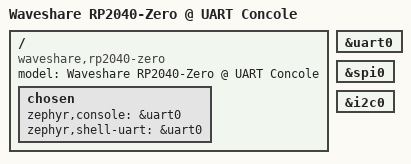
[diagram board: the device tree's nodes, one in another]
/*
 * Copyright (c) 2023-2025 TiaC Systems
 * SPDX-License-Identifier: Apache-2.0
 */

/dts-v1/;

/ {
	model = "Waveshare RP2040-Zero @ UART Concole";
	compatible = "waveshare,rp2040-zero", "waveshare,rp2040-zero-uartcons";

	chosen {
		zephyr,console = &uart0;
		zephyr,shell-uart = &uart0;
	};
};

#include "waveshare_rp2040-mini.dtsi"
#include "waveshare_rp2040-2mb.dtsi"

#include "rp2040mini_led_ws2812.dtsi"
#include "rp2040mini_connector.dtsi"
#include "rp2040mini_pads.dtsi"

rp2040mini_serial: &uart0 {};
rp2040mini_spi: &spi0 {};
rp2040mini_i2c: &i2c0 {};
